# TIMER2 register map
Registers from a debugger description file.
Registers are 32-bit, read-only, no defined reset value unless marked. A register's access mark holds for its fields unless they carry their own. Addresses are absolute; registers are grouped by the start of their names; lines under a group give offsets from that group; [hi:lo] are bit positions; {n}, {i} and the like mark numbered series; 'fields as' and 'values as' point back to an identical list; <NAME> marks a mode.

## Timer2
{0x51002000+0x20*i} Timer2/LoadCount_{i} access not given (i=0..5)
  [15:0] LoadCount
{0x51002004+0x20*i} Timer2/CurrentCount_{i} (i=0..5)
  [15:0] CurrentCount
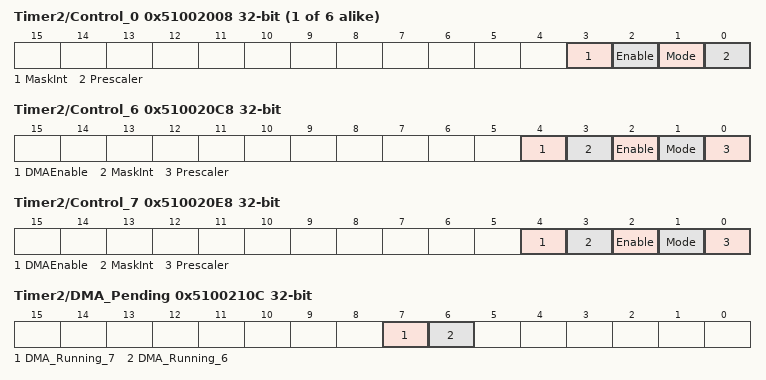
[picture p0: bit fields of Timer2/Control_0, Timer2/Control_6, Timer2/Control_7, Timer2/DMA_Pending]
{0x51002008+0x20*i} Timer2/Control_{i} access not given (i=0..5)
  [3] MaskInt, [2] Enable, [1] Mode, [0] Prescaler
{0x5100200C+0x20*i} Timer2/ClearInt_{i} (i=0..7)
  [0] ClearInt
{0x51002010+0x20*i} Timer2/StatusInt0_{i} (i=0..7)
  [0] StatusInt0
{0x51002014+0x20*i} Timer2/StatusInt1_{i} (i=0..7)
  [0] StatusInt1
0x510020C0 Timer2/LoadCount_6 access not given
  [31:0] LoadCount
0x510020C4 Timer2/CurrentCount_6
  [31:0] CurrentCount
0x510020C8 Timer2/Control_6 access not given
  [4] DMAEnable, [3] MaskInt, [2] Enable, [1] Mode, [0] Prescaler
0x510020E0 Timer2/LoadCount_7 access not given
  [31:0] LoadCount
0x510020E4 Timer2/CurrentCount_7
  [31:0] CurrentCount
0x510020E8 Timer2/Control_7 access not given
  [4] DMAEnable, [3] MaskInt, [2] Enable, [1] Mode, [0] Prescaler
0x51002100 Timer2/AllClearInt
  [7:0] AllClearInt
0x51002104 Timer2/AllStatusInt0
  [7:0] AllStatusInt0
0x51002108 Timer2/AllStatusInt1
  [7:0] AllStatusInt1
0x5100210C Timer2/DMA_Pending
  [7] DMA_Running_7, [6] DMA_Running_6
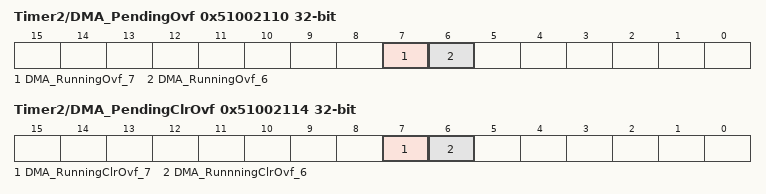
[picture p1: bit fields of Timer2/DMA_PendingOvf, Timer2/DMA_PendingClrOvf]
0x51002110 Timer2/DMA_PendingOvf
  [7] DMA_RunningOvf_7, [6] DMA_RunningOvf_6
0x51002114 Timer2/DMA_PendingClrOvf access not given
  [7] DMA_RunningClrOvf_7, [6] DMA_RunnningClrOvf_6
